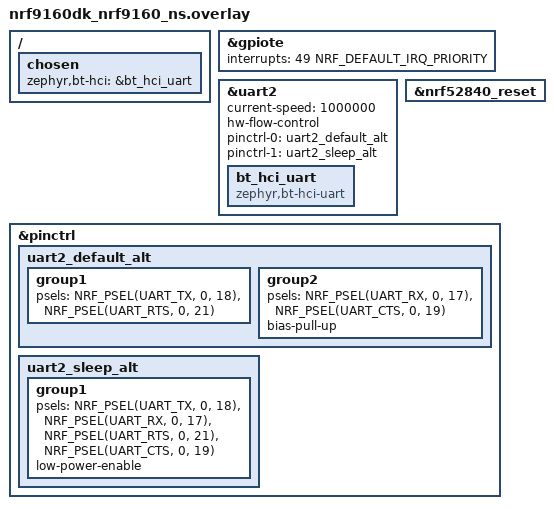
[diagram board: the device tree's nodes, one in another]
/*
 * Copyright (c) 2024 Nordic Semiconductor ASA
 *
 * SPDX-License-Identifier: LicenseRef-Nordic-5-Clause
 */
/* Use the reset line that is available until v0.14.0 of the DK. */
#include <nrf9160/nrf9160dk_nrf52840_reset_on_if5.dtsi>

/ {
	chosen {
		zephyr,bt-hci=&bt_hci_uart;
	};
};

&gpiote {
	interrupts = <49 NRF_DEFAULT_IRQ_PRIORITY>;
};

&uart2 {
	current-speed = <1000000>;
	status = "okay";
	hw-flow-control;

	pinctrl-0 = <&uart2_default_alt>;
	pinctrl-1 = <&uart2_sleep_alt>;
	pinctrl-names = "default", "sleep";
	bt_hci_uart: bt_hci_uart {
		compatible = "zephyr,bt-hci-uart";
		status = "okay";
	};
};

&nrf52840_reset {
	status = "okay";
};

&pinctrl {
	uart2_default_alt: uart2_default_alt {
		group1 {
			psels = <NRF_PSEL(UART_TX, 0, 18)>,
				<NRF_PSEL(UART_RTS, 0, 21)>;
			};
		group2 {
			psels = <NRF_PSEL(UART_RX, 0, 17)>,
				<NRF_PSEL(UART_CTS, 0, 19)>;
				bias-pull-up;
		};
	};

	uart2_sleep_alt: uart2_sleep_alt {
		group1 {
			psels = <NRF_PSEL(UART_TX, 0, 18)>,
				<NRF_PSEL(UART_RX, 0, 17)>,
				<NRF_PSEL(UART_RTS, 0, 21)>,
				<NRF_PSEL(UART_CTS, 0, 19)>;
			low-power-enable;
		};
	};

};
